# myChip register map
Vendor: ARM Ltd.; Series: ARMCM3; File version: 1.2
CPU: CM3 r2p1, little endian, no MPU, no FPU, 3 interrupt priority bits
Registers are 32-bit, read-write, reset 0x0 unless marked. A register's access mark holds for its fields unless they carry their own. Offsets are from the block's base; [hi:lo] are bit positions.

## SPI0
Base 0x40012000
Same registers: SPI1 0x40013000
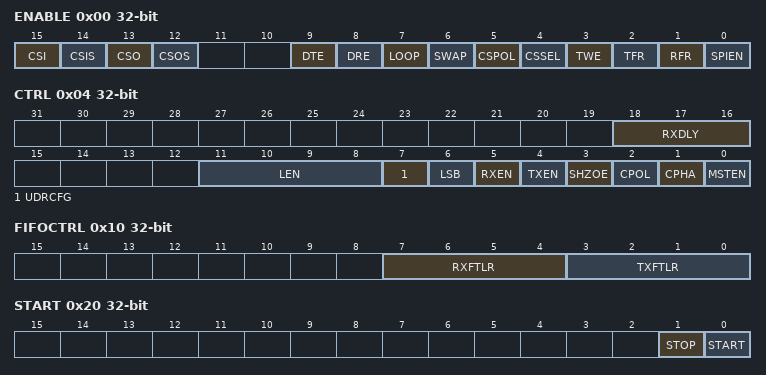
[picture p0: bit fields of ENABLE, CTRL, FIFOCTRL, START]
0x00 ENABLE — SPI Enable Register
  [15] CSI — SPI CS软件输入（SPI Chip Select Software Input）
  [14] CSIS — SPI CS输入选择（SPI Chip Select Input Select）
  [13] CSO — SPI CS软件输出（SPI Chip Select Software Output）
  [12] CSOS — SPI CS输出选择（SPI Chip Select Output Select）
  [9] DTE — SPI发送DMA使能（SPI TX DMA Enable）
  [8] DRE — SPI接收DMA使能（SPI RX DMA Enable）
  [7] LOOP — SPI Loopback使能位（SPI Loopback Enable）
  [6] SWAP — SPI MOSI和MISO引脚交换（SPI MOSI and MISO Pins Swap Enable）
  [5] CSPOL — SPI CS状态极性选择（SPI Chip Select Polarity Select）
  [4] CSSEL — SPI CS模式选择（SPI Chip Select Mode Select）
  [3] TWE — SPI三线使能（SPI three-Wire Enable）
  [2] TFR — SPI TXFIFO复位（SPI TXFIFO RESET）
  [1] RFR — SPI RXFIFO复位（SPI RXFIFO RESET）
  [0] SPIEN ro — SPI使能位（SPI Enable）
0x04 CTRL — SPI Control Register
  [18:16] RXDLY — SPI接收数据采样延迟（SPI Master Rx Data Delay Chain ）
  [11:8] LEN — SPI串行数据长度（SPI Serial Data Length Select）
  [7] UDRCFG — SPI下溢条件时从机发送器行为 (SPI Behavior of slave transmitter at underrun condition)
  [6] LSB — SPI LSB使能（LSB Enable）
  [5] RXEN — SPI接收使能（SPI RX Enable）
  [4] TXEN — SPI发送使能（SPI TX Enable）
  [3] SHZOE — SPI从机输出高阻态使能位（SPI Slave High-Z Output Enable ）
  [2] CPOL — SPI串行时钟极性（SPI CK Polarity）
  [1] CPHA — SPI串行时钟相位（SPI CK Phase）
  [0] MSTEN — SPI的主机使能位（SPI Master Enable）
0x08 BAUD — SPI Baud Rate Registers
  [11:1] BAUD — SPI时钟分频器（SPI Baud Rate）
0x10 FIFOCTRL — SPI FIFO Control Register
  [7:4] RXFTLR — SPI RXFIFO满中断阈值（SPI RXFIFO Full Threshold）
  [3:0] TXFTLR — SPI TXFIFO空中断阈值（SPI TXFIFO Empty Threshold）
0x14 CNT — SPI Count Registers
  [15:0] DCNT — SPI主机传输数据量（SPI Transmittion Data Count）
0x18 RCNT — SPI Remain Count Register
  [15:0] RCNT ro — SPI主机传输剩余数据量（SPI Transmittion Remain Count）
0x20 START — SPI Count Start Register
  [1] STOP — SPI主机传输停止（SPI Master Transmittion Stop）
  [0] START — SPI主机传输开始（SPI Master Transmittion Start）
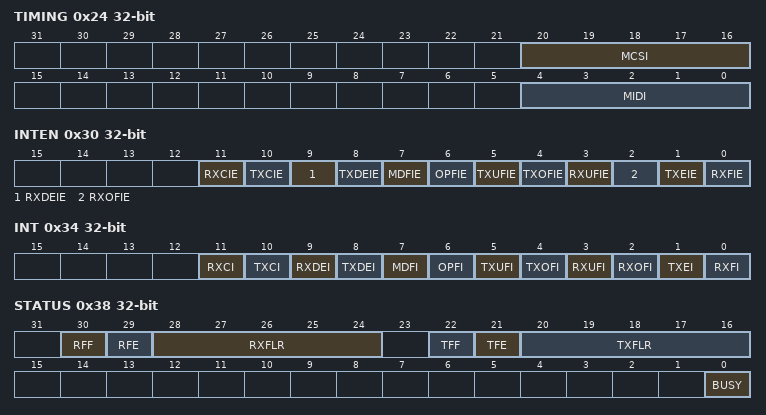
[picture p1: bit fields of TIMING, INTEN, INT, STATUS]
0x24 TIMING — SPI Timing Register
  [20:16] MCSI — SPI主模式CS空闲 (SPI Master Chip Select Idleness)
  [4:0] MIDI — SPI主模式数据间空闲 (SPI Master Inter-Data Idleness)
0x30 INTEN — SPI Interrupt Enable Registers
  [11] RXCIE — SPI接收帧完成中断使能（SPI RX Complete Interrupt Enable）
  [10] TXCIE — SPI发送帧完成中断使能（SPI TX Complete Interrupt Enable）
  [9] RXDEIE — SPI接收完成中断使能（SPI RX Done Interrupt Enable）
  [8] TXDEIE — SPI发送完成中断使能（SPI TX Done Interrupt Enable）
  [7] MDFIE — SPI主从模式错误中断使能（SPI Transmission Mode Fault Interrupt Enable）
  [6] OPFIE — SPI主从操作错误中断使能（SPI Transmission Operation Fault Interrupt Enable）
  [5] TXUFIE — SPI从机发送模式下溢中断使能（SPI Slave Transmission Mode Underflow Interrupt Enable）
  [4] TXOFIE — SPI TXFIFO溢出中断使能（SPI TXFIFO Overflow Interrupt Enable）
  [3] RXUFIE — SPI RXFIFO下溢中断使能（SPI RXFIFO Underflow Interrupt Enable）
  [2] RXOFIE — SPI RXFIFO溢出中断使能（SPI RXFIFO Overflow Interrupt Enable）
  [1] TXEIE — SPI TXFIFO空阈值中断使能（SPI TXFIFO Empty Threshold Interrupt Enable）
  [0] RXFIE — SPI RXFIFO满阈值中断使能（SPI RXFIFO Full Threshold Interrupt Enable）
0x34 INT — SPI Interrupt Registers
  [11] RXCI — SPI接收帧完成中断（SPI RX Complete Interrupt）
  [10] TXCI — SPI发送帧完成中断（SPI TX Complete Interrupt）
  [9] RXDEI — SPI接收完成中断（SPI RX Done Interrupt ）
  [8] TXDEI — SPI发送完成中断（SPI TX Done Interrupt ）
  [7] MDFI — SPI主从机模式错误中断（SPI Transmission Mode Fault Interrupt）
  [6] OPFI — SPI主从机操作错误中断（SPI Transmission Operation Fault Interrupt）
  [5] TXUFI — SPI从机发送模式下溢中断（SPI Slave Transmission Mode Underflow Interrupt）
  [4] TXOFI — SPI TXFIFO溢出中断（SPI TXFIFO Overflow Interrupt）
  [3] RXUFI — SPI RXFIFO下溢中断（SPI RXFIFO Underflow Interrupt）
  [2] RXOFI — SPI RXFIFO溢出中断（SPI RXFIFO Overflow Interrupt）
  [1] TXEI ro — SPI TXFIFO空阈值中断（SPI TXFIFO Empty Threshold Interrupt ）
  [0] RXFI ro — SPI RXFIFO满阈值中断（SPI RXFIFO Full Threshold Interrupt ）
0x38 STATUS — SPI Status Register
  [30] RFF ro — SPI RXFIFO满标志（SPI RXFIFO Full Flag）
  [29] RFE ro — SPI RXFIFO空标志（SPI RXFIFO Empty Flag）
  [28:24] RXFLR ro — SPI RXFIFO实时剩余数据量（SPI RXFIFO Level Register）
  [22] TFF ro — SPI TXFIFO满标志（SPI TXFIFO Full Flag）
  [21] TFE ro — SPI TXFIFO空标志（SPI TXFIFO Empty Flag）
  [20:16] TXFLR ro — SPI TXFIFO实时剩余数据量（SPI TXFIFO Level Register）
  [0] BUSY ro — SPI状态机忙状态（SPI FSM Busy Status）
0x40 TDR — SPI TXFIFO Data Registers
  [15:0] TD — SPI数据写寄存器（SPI Data Write Register）
0x44 RDR — SPI RXFIFO Data Registers
  [15:0] RD ro — SPI数据读寄存器（SPI Data Read Register）
0x48 UDRDR — SPI Underrun Data Register
  [15:0] UDRDR — SPI从模式下溢时数据写寄存器 (SPI Data At Slave Underflow Condition)
